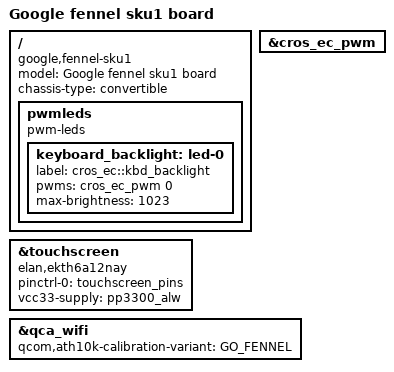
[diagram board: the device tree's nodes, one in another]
// SPDX-License-Identifier: (GPL-2.0 OR MIT)
/*
 * Copyright 2021 Google LLC
 */

/dts-v1/;
#include "mt8183-kukui-jacuzzi-fennel.dtsi"
#include "mt8183-kukui-audio-da7219-rt1015p.dtsi"

/ {
	model = "Google fennel sku1 board";
	chassis-type = "convertible";
	compatible = "google,fennel-sku1", "google,fennel", "mediatek,mt8183";

	pwmleds {
		compatible = "pwm-leds";
		keyboard_backlight: led-0 {
			label = "cros_ec::kbd_backlight";
			pwms = <&cros_ec_pwm 0>;
			max-brightness = <1023>;
		};
	};
};

&cros_ec_pwm {
	status = "okay";
};

&touchscreen {
	compatible = "elan,ekth6a12nay";

	pinctrl-names = "default";
	pinctrl-0 = <&touchscreen_pins>;

	vcc33-supply = <&pp3300_alw>;
};

&qca_wifi {
	qcom,ath10k-calibration-variant = "GO_FENNEL";
};

